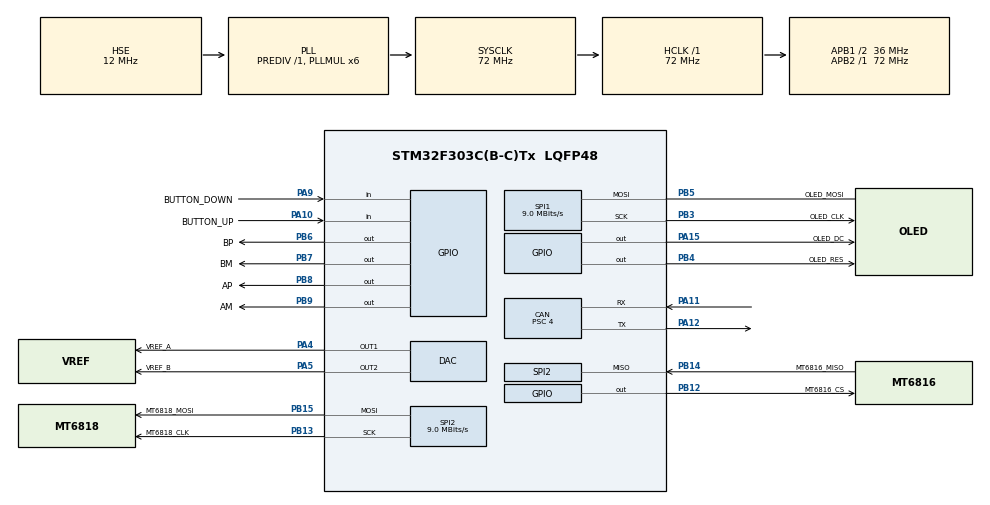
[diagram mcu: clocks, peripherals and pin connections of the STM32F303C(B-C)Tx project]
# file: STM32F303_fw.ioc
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CAN.AWUM=ENABLE
CAN.BS1=CAN_BS1_4TQ
CAN.BS2=CAN_BS2_4TQ
CAN.CalculateBaudRate=1000000
CAN.CalculateTimeBit=1000
CAN.CalculateTimeQuantum=111.11111111111111
CAN.NART=ENABLE
CAN.Prescaler=4
Mcu.Family=STM32F3
Mcu.Name=STM32F303C(B-C)Tx
Mcu.Package=LQFP48
NVIC.CAN_RX1_IRQn=true\:2\:1\:true\:false\:true\:true\:true\:true
NVIC.PriorityGroup=NVIC_PRIORITYGROUP_2
NVIC.TIM3_IRQn=true\:2\:2\:true\:false\:true\:true\:true\:true
NVIC.TIM4_IRQn=true\:3\:2\:true\:false\:true\:true\:true\:true
NVIC.USB_LP_CAN_RX0_IRQn=true\:2\:1\:true\:false\:true\:true\:true\:true
PA10.GPIO_Label=BUTTON_UP
PA10.GPIO_PuPd=GPIO_PULLUP
PA10.Signal=GPIO_Input
PA11.Mode=CAN_Activate
PA11.Signal=CAN_RX
PA12.Mode=CAN_Activate
PA12.Signal=CAN_TX
PA13.Mode=Serial_Wire
PA13.Signal=SYS_JTMS-SWDIO
PA14.Mode=Serial_Wire
PA14.Signal=SYS_JTCK-SWCLK
PA15.GPIO_Label=OLED_DC
PA15.GPIO_PuPd=GPIO_PULLUP
PA15.Signal=GPIO_Output
PA4.GPIO_Label=VREF_A
PA4.Signal=COMP_DAC1_group
PA5.GPIO_Label=VREF_B
PA5.Signal=COMP_DAC2_group
PA9.GPIO_Label=BUTTON_DOWN
PA9.GPIO_PuPd=GPIO_PULLUP
PA9.Signal=GPIO_Input
PB12.GPIO_Label=MT6816_CS
PB12.Signal=GPIO_Output
PB13.GPIO_Label=MT6818_CLK
PB13.Mode=Full_Duplex_Master
PB13.Signal=SPI2_SCK
PB14.GPIO_Label=MT6816_MISO
PB14.Mode=Full_Duplex_Master
PB14.Signal=SPI2_MISO
PB15.GPIO_Label=MT6818_MOSI
PB15.Mode=Full_Duplex_Master
PB15.Signal=SPI2_MOSI
PB3.GPIO_Label=OLED_CLK
PB3.Mode=Simplex_Bidirectional_Master
PB3.Signal=SPI1_SCK
PB4.GPIO_Label=OLED_RES
PB4.GPIO_PuPd=GPIO_PULLUP
PB4.Signal=GPIO_Output
PB5.GPIO_Label=OLED_MOSI
PB5.Mode=Simplex_Bidirectional_Master
PB5.Signal=SPI1_MOSI
PB6.GPIO_FM6=SYSCFG_CFGR1_I2C_PB6_FMP
PB6.GPIO_Label=BP
PB6.GPIO_ModeDefaultOutputPP=GPIO_MODE_OUTPUT_PP
PB6.GPIO_PuPd=GPIO_NOPULL
PB6.GPIO_Speed=GPIO_SPEED_FREQ_HIGH
PB6.PinState=GPIO_PIN_SET
PB6.Signal=GPIO_Output
PB7.GPIO_FM7=SYSCFG_CFGR1_I2C_PB7_FMP
PB7.GPIO_Label=BM
PB7.GPIO_ModeDefaultOutputPP=GPIO_MODE_OUTPUT_PP
PB7.GPIO_PuPd=GPIO_NOPULL
PB7.GPIO_Speed=GPIO_SPEED_FREQ_HIGH
PB7.PinState=GPIO_PIN_SET
PB7.Signal=GPIO_Output
PB8.GPIO_FM8=SYSCFG_CFGR1_I2C_PB8_FMP
PB8.GPIO_Label=AP
PB8.GPIO_ModeDefaultOutputPP=GPIO_MODE_OUTPUT_PP
PB8.GPIO_PuPd=GPIO_NOPULL
PB8.GPIO_Speed=GPIO_SPEED_FREQ_HIGH
PB8.PinState=GPIO_PIN_SET
PB8.Signal=GPIO_Output
PB9.GPIO_FM9=SYSCFG_CFGR1_I2C_PB9_FMP
PB9.GPIO_Label=AM
PB9.GPIO_ModeDefaultOutputPP=GPIO_MODE_OUTPUT_PP
PB9.GPIO_PuPd=GPIO_NOPULL
PB9.GPIO_Speed=GPIO_SPEED_FREQ_HIGH
PB9.PinState=GPIO_PIN_SET
PB9.Signal=GPIO_Output
PF0-OSC_IN.Mode=HSE-External-Oscillator
PF0-OSC_IN.Signal=RCC_OSC_IN
PF1-OSC_OUT.Mode=HSE-External-Oscillator
PF1-OSC_OUT.Signal=RCC_OSC_OUT
ProjectManager.HeapSize=0x200
ProjectManager.StackSize=0x400
ProjectManager.TargetToolchain=STM32CubeIDE
RCC.AHBFreq_Value=72000000
RCC.APB1CLKDivider=RCC_HCLK_DIV2
RCC.APB1Freq_Value=36000000
RCC.APB1TimFreq_Value=72000000
RCC.APB2Freq_Value=72000000
RCC.APB2TimFreq_Value=72000000
RCC.CortexFreq_Value=72000000
RCC.HCLKFreq_Value=72000000
RCC.HSE_Timout=100
RCC.HSE_VALUE=12000000
RCC.HSI_VALUE=8000000
RCC.LSE_VALUE=32768
RCC.PLLMUL=RCC_PLL_MUL6
RCC.PLLSourceVirtual=RCC_PLLSOURCE_HSE
RCC.SYSCLKFreq_VALUE=72000000
RCC.SYSCLKSourceVirtual=RCC_SYSCLKSOURCE_PLLCLK
RCC.USBFreq_Value=72000000
SH.COMP_DAC1_group.0=DAC_OUT1,DAC_OUT1
SH.COMP_DAC2_group.0=DAC_OUT2,Enable_DAC_OUT2
SPI1.BaudRatePrescaler=SPI_BAUDRATEPRESCALER_8
SPI1.CLKPhase=SPI_PHASE_1EDGE
SPI1.CLKPolarity=SPI_POLARITY_LOW
SPI1.CalculateBaudRate=9.0 MBits/s
SPI1.DataSize=SPI_DATASIZE_8BIT
SPI1.Direction=SPI_DIRECTION_1LINE
SPI1.Mode=SPI_MODE_MASTER
SPI1.VirtualType=VM_MASTER
SPI2.BaudRatePrescaler=SPI_BAUDRATEPRESCALER_4
SPI2.CLKPhase=SPI_PHASE_2EDGE
SPI2.CLKPolarity=SPI_POLARITY_HIGH
SPI2.CalculateBaudRate=9.0 MBits/s
SPI2.DataSize=SPI_DATASIZE_16BIT
SPI2.Direction=SPI_DIRECTION_2LINES
SPI2.Mode=SPI_MODE_MASTER
SPI2.VirtualType=VM_MASTER
TIM3.AutoReloadPreload=TIM_AUTORELOAD_PRELOAD_ENABLE
TIM3.Period=49
TIM3.Prescaler=71
TIM4.AutoReloadPreload=TIM_AUTORELOAD_PRELOAD_ENABLE
TIM4.Period=19999
TIM4.Prescaler=71
VP_TIM3_VS_ClockSourceINT.Mode=Internal
VP_TIM4_VS_ClockSourceINT.Mode=Internal
board=custom

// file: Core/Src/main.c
/* USER CODE BEGIN Header */
/**
  ******************************************************************************
  * @file           : main.c
  * @brief          : Main program body
  ******************************************************************************
  * @attention
  *
  * Copyright (c) 2024 STMicroelectronics.
  * All rights reserved.
  *
  * This software is licensed under terms that can be found in the LICENSE file
  * in the root directory of this software component.
  * If no LICENSE file comes with this software, it is provided AS-IS.
  *
  ******************************************************************************
  */
/* USER CODE END Header */
#include "main.h"
#include "can.h"
#include "dac.h"
#include "spi.h"
#include "tim.h"
#include "gpio.h"

/* USER CODE BEGIN Includes */
#include "selfmain.h"
/* USER CODE END Includes */

void SystemClock_Config(void);

int main(void)
{
  /* USER CODE BEGIN 1 */
    HAL_RCC_DeInit();
  /* USER CODE END 1 */

  /* MCU Configuration--------------------------------------------------------*/

  /* Reset of all peripherals, Initializes the Flash interface and the Systick. */
  HAL_Init();

  /* Configure the system clock */
  SystemClock_Config();

  /* Initialize all configured peripherals */
  MX_GPIO_Init();
  MX_CAN_Init();
  MX_DAC_Init();
  MX_SPI1_Init();
  MX_SPI2_Init();
  MX_TIM3_Init();
  MX_TIM4_Init();

  /* Infinite loop */
  /* USER CODE BEGIN WHILE */
    SelfMain();
    while (1) {
    /* USER CODE END WHILE */

    }
}

void SystemClock_Config(void)
{
  RCC_OscInitTypeDef RCC_OscInitStruct = {0};
  RCC_ClkInitTypeDef RCC_ClkInitStruct = {0};

  /** Initializes the RCC Oscillators according to the specified parameters
  * in the RCC_OscInitTypeDef structure.
  */
  RCC_OscInitStruct.OscillatorType = RCC_OSCILLATORTYPE_HSE;
  RCC_OscInitStruct.HSEState = RCC_HSE_ON;
  RCC_OscInitStruct.HSEPredivValue = RCC_HSE_PREDIV_DIV1;
  RCC_OscInitStruct.HSIState = RCC_HSI_ON;
  RCC_OscInitStruct.PLL.PLLState = RCC_PLL_ON;
  RCC_OscInitStruct.PLL.PLLSource = RCC_PLLSOURCE_HSE;
  RCC_OscInitStruct.PLL.PLLMUL = RCC_PLL_MUL6;
  if (HAL_RCC_OscConfig(&RCC_OscInitStruct) != HAL_OK)
  {
    Error_Handler();
  }

  /** Initializes the CPU, AHB and APB buses clocks
  */
  RCC_ClkInitStruct.ClockType = RCC_CLOCKTYPE_HCLK|RCC_CLOCKTYPE_SYSCLK
                              |RCC_CLOCKTYPE_PCLK1|RCC_CLOCKTYPE_PCLK2;
  RCC_ClkInitStruct.SYSCLKSource = RCC_SYSCLKSOURCE_PLLCLK;
  RCC_ClkInitStruct.AHBCLKDivider = RCC_SYSCLK_DIV1;
  RCC_ClkInitStruct.APB1CLKDivider = RCC_HCLK_DIV2;
  RCC_ClkInitStruct.APB2CLKDivider = RCC_HCLK_DIV1;

  if (HAL_RCC_ClockConfig(&RCC_ClkInitStruct, FLASH_LATENCY_2) != HAL_OK)
  {
    Error_Handler();
  }
}

void Error_Handler(void)
{
    __disable_irq();
    while (1) {
    }
}
